# STM32H7P5 register map
File version: 2.0.0
CPU: CM7 r1p2, little endian, MPU, FPU, 4 interrupt priority bits
Registers are 32-bit, read-write, reset 0x0 unless marked. A register's access mark holds for its fields unless they carry their own. Offsets are from the block's base; [hi:lo] are bit positions; lines under a group give offsets from that group; {n}, {i} and the like mark numbered series; 'fields as' and 'values as' point back to an identical list.

## I3C1 — I3C register block
Base 0x40006000
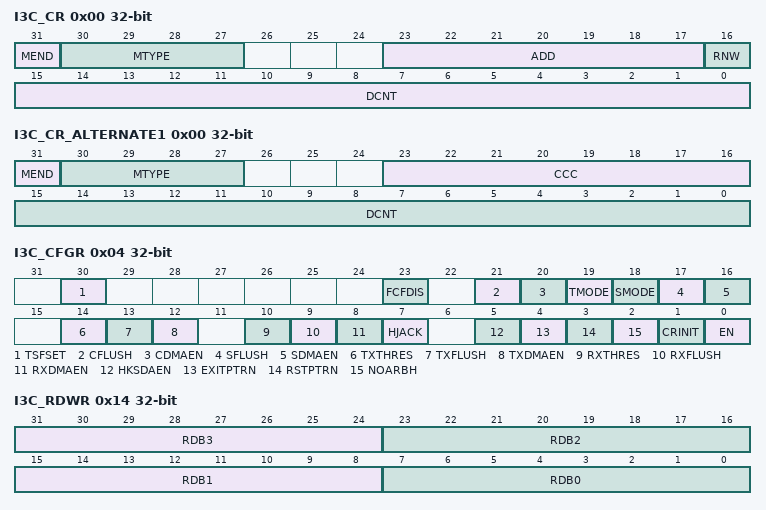
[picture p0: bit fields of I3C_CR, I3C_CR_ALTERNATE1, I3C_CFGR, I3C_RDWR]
0x00 I3C_CR wo — I3C message control register
  [31] MEND — Message end type/last message of a frame (when the I3C acts as controller)
    0=this message from controller is followed by a repeated start (Sr), before another message must be emitted; 1=this message from controller ends with a stop (P), being the last message of a frame
  [30:27] MTYPE — Message type (whatever I3C acts as controller/target)
    0=B_0x0_WHEN_I3C_ACTS_AS_I3C_CONTROLLER (SCL clock is forced to stop until a next control word is executed); 1=B_0x1_WHEN_I3C_ACTS_AS_I3C_CONTROLLER (header message); 2=B_0x2_WHEN_I3C_ACTS_AS_I3C_CONTROLLER (private message (refer to Figure726)); 3=B_0x3_WHEN_I3C_ACTS_AS_I3C_CONTROLLER (direct message (second part of an I3C SDR direct CCC command) (refer to Figure719)); 4=B_0x4_WHEN_I3C_ACTS_AS_I3C_CONTROLLER (legacy Iless thansup>2less than/sup>C message (refer to Figure728)); 8=B_0x8_WHEN_I3C_ACTS_AS_I3C_TARGET (hot-join request (W) (refer to Figure731)); 9=B_0x9_WHEN_I3C_ACTS_AS_I3C_TARGET (controller-role request (W) (refer to Figure732)); 10=B_0xA_WHEN_I3C_ACTS_AS_I3C_TARGET (IBI (in-band interrupt) request (R) (refer to Figure730))
  [23:17] ADD — 7-bit I3C dynamic / Iless thansup>2less than/sup>C static target address (when I3C acts as controller)
  [16] RNW — Read / non-write message (when I3C acts as controller)
    0=write message; 1=read message
  [15:0] DCNT — Count of data to transfer during a read or write message, in bytes (whatever I3C acts as controller/target)
    0=no data to transfer; 1=1 byte; 2=2 bytes; 0xFFFF=64 Kbytes - 1 byte
0x00 I3C_CR_ALTERNATE1 wo (alternate view of I3C_CR) — I3C message control register
  [31] MEND — Message end type/last message of a frame (when I3C acts as controller)
    0=this message from controller is followed by a repeated start (Sr), before another message must be emitted; 1=the message from the controller ends with a stop (P), being the last message of a frame
  [30:27] MTYPE — Message type (when I3C acts as controller)
    6=B_0x6_WHEN_I3C_ACTS_AS_I3C_CONTROLLER (broadcast/direct CCC command (refer to Table556, Figure719, Figure720, Figure721))
  [23:16] CCC — 8-bit CCC code (when I3C acts as controller)
  [15:0] DCNT — Count of related data to the CCC command to transfer as CCC defining bytes, or CCC sub-command bytes, or CCC data bytes, in bytes
    values as I3C_CR.DCNT
0x04 I3C_CFGR — I3C configuration register
  [30] TSFSET wo — Frame transfer set (software trigger) (when I3C acts as controller)
    0=no action; 1=setting this bit initiates a frame transfer by causing the hardware to assert the flag CFNFF in the I3C_EVR register (C-FIFO not full and a control word is needed)
  [23] FCFDIS — FCF generation disable (when I3C acts as controller)
    0=enable the generation of the flag FCF in the I3C_EVR register; 1=disable the generation of the flag FCF in the I3C_EVR register
  [21] CFLUSH wo — C-FIFO flush (when I3C acts as controller)
    0=no action; 1=flush C-FIFO
  [20] CDMAEN — C-FIFO DMA request enable (when I3C acts as controller)
    0=DMA mode is disabled for C-FIFO; 1=DMA mode is enabled for C-FIFO
  [19] TMODE — Transmit mode (when I3C acts as controller)
    0=C-FIFO and TX-FIFO are not preloaded before starting to emit a frame transfer; 1=C-FIFO and TX-FIFO are first preloaded (also TX-FIFO if needed, depending on the frame format) before starting to emit a frame transfer. Refer to Section52.10.2 for more details.
  [18] SMODE — S-FIFO enable / status receive mode (when I3C acts as controller)
    0=S-FIFO is disabled; 1=S-FIFO is enabled
  [17] SFLUSH wo — S-FIFO flush (when I3C acts as controller)
    0=no action; 1=flush S-FIFO
  [16] SDMAEN — S-FIFO DMA request enable (when I3C acts as controller)
    0=DMA mode is disabled for reading status register I3C_SR; 1=DMA mode is enabled for reading status register I3C_SR
  [14] TXTHRES — TX-FIFO threshold (whatever I3C acts as controller/target)
    0=1-byte threshold; 1=1-word / 4-byte threshold
  [13] TXFLUSH wo — TX-FIFO flush (whatever I3C acts as controller/target)
    0=no action; 1=flush TX-FIFO
  [12] TXDMAEN — TX-FIFO DMA request enable (whatever I3C acts as controller/target)
    0=DMA mode is disabled for TX-FIFO; 1=DMA mode is enabled for TX-FIFO
  [10] RXTHRES — RX-FIFO threshold (whatever I3C acts as controller/target)
    0=1-byte threshold; 1=1-word/4-bytes threshold
  [9] RXFLUSH wo — RX-FIFO flush (whatever I3C acts as controller/target)
    0=no action; 1=flush RX-FIFO
  [8] RXDMAEN — RX-FIFO DMA request enable (whatever I3C acts as controller/target)
    0=DMA mode is disabled for RX-FIFO; 1=DMA mode is enabled for RX-FIFO
  [7] HJACK — Hot-join request acknowledge (when I3C acts as a controller)
    0=hot-join request is not acknowledged; 1=hot-join request is acknowledged
  [5] HKSDAEN — High-keeper enable on SDA line (when I3C acts as a controller)
    0=High-keeper is disabled; 1=High-keeper is enabled, and the weak pull-up is effective on the T bit, instead of the open-drain class pull-up
  [4] EXITPTRN — HDR exit pattern enable (when I3C acts as a controller)
    0=HDR exit pattern is not sent after the issued message header (MTYPE[3:0]=0001 in the I3C_CR register). This is used to send the header, to test ownership of the bus when there is a suspicion of a problem after controller-role hand-off (new controller did not assert its controller-role by accessing the previous one in less than the delay defined by the activity state).; 1=HDR exit pattern is sent after the issued message header (MTYPE[3:0]=0001). This is used on a controller error detection and escalation handling, in case of a not responding target to a private message or a direct read CCC.
  [3] RSTPTRN — HDR reset pattern enable (when I3C acts as a controller)
    0=standard stop emitted at the end of a frame; 1=HDR reset pattern is inserted before the stop of any emitted frame that includes a RSTACT CCC command
  [2] NOARBH — No arbitrable header after a start (when I3C acts as a controller)
    0=An arbitrable header (0b111_1110 + RnW = 0) is emitted after a start and before a legacy Iless thansup>2less than/sup>C message or an I3C SDR private read/write message (default); 1=No arbitrable header
  [1] CRINIT — Initial controller/target role
    0=target role; 1=controller role
  [0] EN — I3C enable (whatever I3C acts as controller/target)
    0=I3C is disabled; 1=I3C is enabled
0x10 I3C_RDR ro — I3C receive data byte register
  [7:0] RDB0 — 8-bit received data on I3C bus.
0x14 I3C_RDWR ro — I3C receive data word register
  [31:24] RDB3 — 8-bit received data (latest byte on I3C bus).
  [23:16] RDB2 — 8-bit received data (next byte after RDB1 on I3C bus).
  [15:8] RDB1 — 8-bit received data (next byte after RDB0 on I3C bus).
  [7:0] RDB0 — 8-bit received data (earliest byte on I3C bus).
0x18 I3C_TDR wo — I3C transmit data byte register
  [7:0] TDB0 — 8-bit data to transmit on I3C bus.
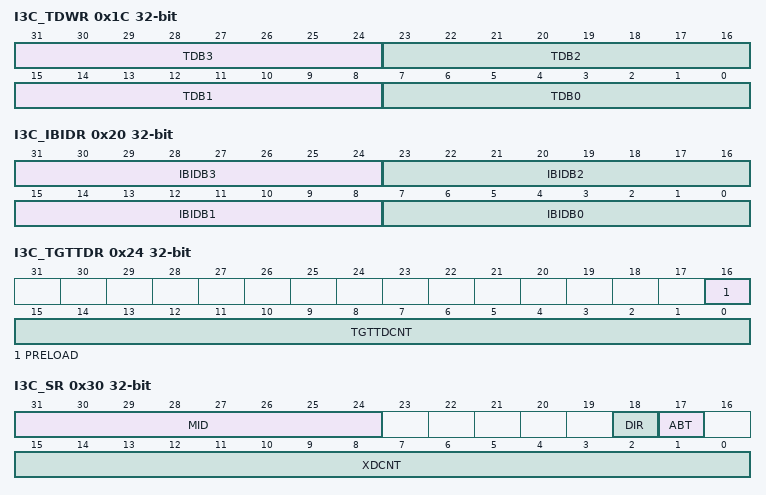
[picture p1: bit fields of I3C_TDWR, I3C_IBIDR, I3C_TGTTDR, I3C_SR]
0x1C I3C_TDWR wo — I3C transmit data word register
  [31:24] TDB3 — 8-bit transmit data (latest byte on I3C bus).
  [23:16] TDB2 — 8-bit transmit data (next byte after TDB1[7:0] on I3C bus).
  [15:8] TDB1 — 8-bit transmit data (next byte after TDB0[7:0] on I3C bus).
  [7:0] TDB0 — 8-bit transmit data (earliest byte on I3C bus)
0x20 I3C_IBIDR — I3C IBI payload data register
  [31:24] IBIDB3 — 8-bit IBI payload data (latest byte on I3C bus).
  [23:16] IBIDB2 — 8-bit IBI payload data (next byte on I3C bus after IBIDB1[7:0]).
  [15:8] IBIDB1 — 8-bit IBI payload data (next byte on I3C bus after IBIDB0[7:0]).
  [7:0] IBIDB0 — 8-bit IBI payload data (earliest byte on I3C bus, MDB[7:0] mandatory data byte).
0x24 I3C_TGTTDR — I3C target transmit configuration register
  [16] PRELOAD — Preload of the TX-FIFO (when I3C is configured as target)
    0=no TX-FIFO preload; 1=TX-FIFO preload
  [15:0] TGTTDCNT — Transmit data counter, in bytes (when I3C is configured as target)
0x30 I3C_SR ro — I3C status register
  [31:24] MID — Message identifier/counter of a given frame (when the I3C acts as controller)
  [18] DIR — Message direction
    0=write; 1=read
  [17] ABT — A private read message is ended prematurely by the target (when the I3C acts as controller)
    0=no early completion from the target; 1=early completion from the target
  [15:0] XDCNT — Data counter
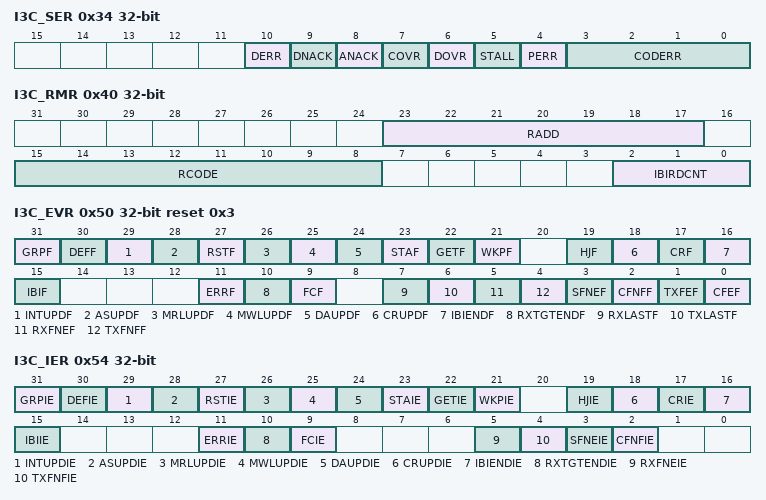
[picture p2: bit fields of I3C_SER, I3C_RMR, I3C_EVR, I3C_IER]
0x34 I3C_SER ro — I3C status error register
  [10] DERR — Data error (when the I3C acts as controller)
    0=no detected error; 1=controller detected a data error during the controller-role hand-off procedure (GETACCCR CCC, formerly known as GETACCMST) when the received target address or/and the parity bit do no match. Active controller keeps controller-role.
  [9] DNACK — Data not acknowledged (when the I3C acts as controller)
    0=no detected error; 1=controller detected that a data byte is not acknowledged by a target, either during:
  [8] ANACK — Address not acknowledged (when the I3C is configured as controller)
    0=no detected error; 1=controller detected that the static/dynamic address was not acknowledged by a target, either during:
  [7] COVR — C-FIFO underrun or S-FIFO overrun (when the I3C acts as controller)
    0=no detected error; 1=controller detected either:
  [6] DOVR — RX-FIFO overrun or TX-FIFO underrun
    0=no detected error; 1=whatever controller or target, hardware detected either:
  [5] STALL — SCL stall error (when the I3C acts as target)
    0=no detected error; 1=target detected that SCL was stable for more than 125 us during an I3C SDR data read (during a direct CCC read, a private read, or an IB)
  [4] PERR — Protocol error
    0=no detected error; 1=whatever controller or target, hardware detected a protocol error, as detailed in CODERR[3:0]
  [3:0] CODERR — Protocol error code/type
    0=CE0 error (transaction after sending CCC):; 1=CE1 error (monitoring error):; 2=CE2 error (no response to broadcast address):; 3=CE3 error (failed controller-role hand-off):; 8=TE0 error (invalid broadcast address 0b111_1110 + W):; 9=TE1 error (CCC code):; 10=TE2 error (write data):; 11=TE3 error (assigned address during dynamic address arbitration):; 12=TE4 error (0b111_1110 + R missing after Sr during dynamic address arbitration):; 13=TE5 error (transaction after detecting CCC):; 14=TE6 error (monitoring error):
0x40 I3C_RMR ro — I3C received message register
  [23:17] RADD — Received target address (when the I3C is configured as controller)
  [15:8] RCODE — Received CCC code (when the I3C is configured as target)
  [2:0] IBIRDCNT — IBI received payload data count (when the I3C is configured as controller)
0x50 I3C_EVR ro reset 0x3 — I3C event register
  [31] GRPF — Group addressing flag (when the I3C acts as target)
  [30] DEFF — DEFTGTS flag (when the I3C acts as target)
  [29] INTUPDF — Interrupt/controller-role/hot-join update flag (when the I3C acts as target)
  [28] ASUPDF — Activity state update flag (when the I3C acts as target)
  [27] RSTF — Reset pattern flag (when the I3C acts as target)
  [26] MRLUPDF — Maximum read length update flag (when the I3C acts as target)
  [25] MWLUPDF — Maximum write length update flag (when the I3C acts as target)
  [24] DAUPDF — Dynamic address update flag (when the I3C acts as target)
  [23] STAF — Get status flag (when the I3C acts as target)
  [22] GETF — Get flag (when the I3C acts as target)
  [21] WKPF — Wake-up/missed start flag (when the I3C acts as target)
  [19] HJF — Hot-join flag (when the I3C acts as controller)
  [18] CRUPDF — Controller-role update flag (when the I3C acts as target)
  [17] CRF — Controller-role request flag (when the I3C acts as controller)
  [16] IBIENDF — IBI end flag (when the I3C acts as target)
  [15] IBIF — IBI flag (when the I3C acts as controller)
  [11] ERRF — Flag (whatever the I3C acts as controller/target)
  [10] RXTGTENDF — Target-initiated read end flag (when the I3C acts as controller)
  [9] FCF — Frame complete flag (whatever the I3C acts as controller/target)
  [7] RXLASTF — Last read data byte/word flag (when the I3C acts as controller)
  [6] TXLASTF — Last written data byte/word flag (whatever the I3C acts as controller/target)
  [5] RXFNEF — RX-FIFO not empty flag (whatever the I3C acts as controller/target)
  [4] TXFNFF — TX-FIFO not full flag (whatever the I3C acts as controller/target)
  [3] SFNEF — S-FIFO not empty flag (when the I3C acts as controller)
  [2] CFNFF — C-FIFO not full flag (when the I3C acts as controller)
  [1] TXFEF — TX-FIFO empty flag (whatever the I3C acts as controller/target)
  [0] CFEF — C-FIFO empty flag (whatever the I3C acts as controller)
0x54 I3C_IER — I3C interrupt enable register
  [all] fields
    0=interrupt disabled; 1=interrupt enabled
  [31] GRPIE — DEFGRPA CCC interrupt enable (when the I3C acts as target)
  [30] DEFIE — DEFTGTS CCC interrupt enable (when the I3C acts as target)
  [29] INTUPDIE — ENEC/DISEC CCC interrupt enable (when the I3C acts as target)
  [28] ASUPDIE — ENTASx CCC interrupt enable (when the I3C acts as target)
  [27] RSTIE — reset pattern interrupt enable (when the I3C acts as target)
  [26] MRLUPDIE — SETMRL CCC interrupt enable (when the I3C acts as target)
  [25] MWLUPDIE — SETMWL CCC interrupt enable (when the I3C acts as target)
  [24] DAUPDIE — ENTDAA/RSTDAA/SETNEWDA CCC interrupt enable (when the I3C acts as target)
  [23] STAIE — format 1 GETSTATUS CCC interrupt enable (when the I3C acts as target)
  [22] GETIE — GETxxx CCC interrupt enable (except GETSTATUS of format 1) (when the I3C acts as target)
  [21] WKPIE — Wake-up interrupt enable (when the I3C acts as target)
  [19] HJIE — Hot-join interrupt enable (when the I3C acts as controller)
  [18] CRUPDIE — Controller-role update interrupt enable (when the I3C acts as target)
  [17] CRIE — Controller-role request interrupt enable (when the I3C acts as controller)
  [16] IBIENDIE — IBI end interrupt enable (when the I3C acts as target)
  [15] IBIIE — IBI request interrupt enable (when the I3C acts as controller)
  [11] ERRIE — error interrupt enable (whatever the I3C acts as controller/target)
  [10] RXTGTENDIE — target-initiated read end interrupt enable (when the I3C acts as controller)
  [9] FCIE — frame complete interrupt enable (whatever the I3C acts as controller/target)
  [5] RXFNEIE — RX-FIFO not empty interrupt enable (whatever the I3C acts as controller/target)
  [4] TXFNFIE — TX-FIFO not full interrupt enable (whatever the I3C acts as controller/target)
  [3] SFNEIE — S-FIFO not empty interrupt enable when the I3C acts as controller
  [2] CFNFIE — C-FIFO not full interrupt enable when the I3C acts as controller
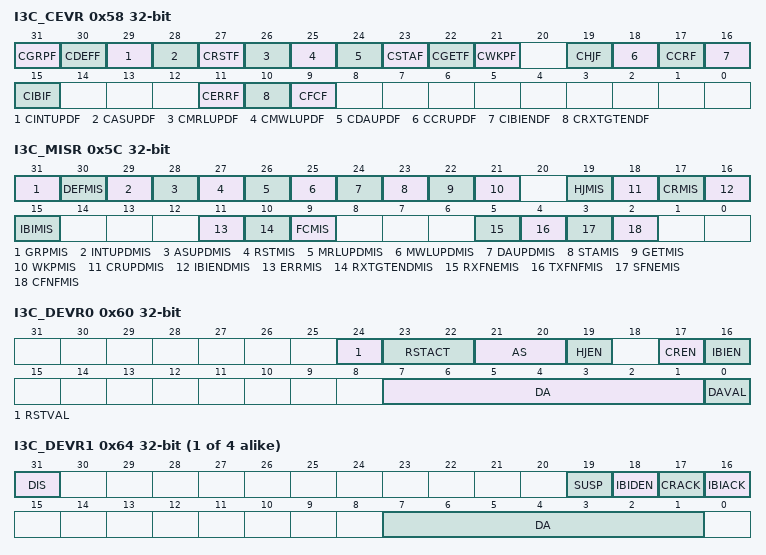
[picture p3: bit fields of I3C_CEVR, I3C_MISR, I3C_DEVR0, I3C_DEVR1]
0x58 I3C_CEVR wo — I3C clear event register
  [31] CGRPF — Clear DEFGRPA CCC flag (when the I3C acts as target)
    0=no effect; 1=clear GRPF
  [30] CDEFF — Clear DEFTGTS CCC flag (when the I3C acts as target)
    0=no effect; 1=clear DEFF
  [29] CINTUPDF — Clear ENEC/DISEC CCC flag (when the I3C acts as target)
    0=no effect; 1=clear CINTUPDF
  [28] CASUPDF — Clear ENTASx CCC flag (when the I3C acts as target)
    0=no effect; 1=clear ASUPDF
  [27] CRSTF — Clear reset pattern flag (when the I3C acts as target)
    0=no effect; 1=clear RSTF
  [26] CMRLUPDF — Clear SETMRL CCC flag (when the I3C acts as target)
    0=no effect; 1=clear MRLUPDF
  [25] CMWLUPDF — Clear SETMWL CCC flag (when the I3C acts as target)
    0=no effect; 1=clear MWLUPDF
  [24] CDAUPDF — Clear ENTDAA/RSTDAA/SETNEWDA CCC flag (when the I3C acts as target)
    0=no effect; 1=clear DAUPDF
  [23] CSTAF — Clear format 1 GETSTATUS CCC flag (when the I3C acts as target)
    0=no effect; 1=clear STAF
  [22] CGETF — Clear GETxxx CCC flag (except GETSTATUS of format 1) (when the I3C acts as target)
    0=no effect; 1=clear GETF
  [21] CWKPF — Clear wake-up flag (when the I3C acts as target)
    0=no effect; 1=clear WKPF
  [19] CHJF — Clear hot-join flag (when the I3C acts as controller)
    0=no effect; 1=clear HJF
  [18] CCRUPDF — Clear controller-role update flag (when the I3C acts as target)
    0=no effect; 1=clear CRUPDF
  [17] CCRF — Clear controller-role request flag (when the I3C acts as controller)
    0=no effect; 1=clear CRF
  [16] CIBIENDF — Clear IBI end flag (when the I3C acts as target)
    0=no effect; 1=clear IBIENDF
  [15] CIBIF — Clear IBI request flag (when the I3C acts as controller)
    0=no effect; 1=clear IBIF
  [11] CERRF — Clear error flag (whatever the I3C acts as controller/target)
    0=no effect; 1=clear ERRF
  [10] CRXTGTENDF — Clear target-initiated read end flag (when the I3C acts as controller)
    0=no effect; 1=clear RXTGTENDF
  [9] CFCF — Clear frame complete flag (whatever the I3C acts as controller/target)
    0=no effect; 1=clear FCF
0x5C I3C_MISR ro — I3C masked interrupt status register
  [31] GRPMIS — DEFGRPA CCC masked interrupt status (when the I3C acts as target)
  [30] DEFMIS — DEFTGTS CCC masked interrupt status (when the I3C acts as target)
  [29] INTUPDMIS — ENEC/DISEC CCC masked interrupt status (when the I3C acts as target)
  [28] ASUPDMIS — ENTASx CCC masked interrupt status (when the I3C acts as target)
  [27] RSTMIS — reset pattern masked interrupt status (when the I3C acts as target)
  [26] MRLUPDMIS — SETMRL CCC masked interrupt status (when the I3C acts as target)
  [25] MWLUPDMIS — SETMWL CCC masked interrupt status (when the I3C acts as target)
  [24] DAUPDMIS — ENTDAA/RSTDAA/SETNEWDA CCC masked interrupt status (when the I3C acts as target)
  [23] STAMIS — format 1 GETSTATUS CCC masked interrupt status (when the I3C acts as target)
  [22] GETMIS — GETxxx CCC masked interrupt status, except GETSTATUS of format 1 (when the I3C acts as target)
  [21] WKPMIS — Wake-up/missed start masked interrupt status (when the I3C acts as target)
  [19] HJMIS — Hot-join masked interrupt status (when the I3C acts as controller)
  [18] CRUPDMIS — Controller-role update masked interrupt status (when the I3C acts as target)
  [17] CRMIS — Controller-role request masked interrupt status (when the I3C acts as controller)
  [16] IBIENDMIS — IBI end masked interrupt status (when the I3C acts as target)
  [15] IBIMIS — IBI request masked interrupt status (when the I3C acts as controller)
  [11] ERRMIS — error masked interrupt status (whatever the I3C acts as controller/target)
  [10] RXTGTENDMIS — target-initiated read end masked interrupt status (when the I3C acts as controller)
  [9] FCMIS — frame complete masked interrupt status (whatever the I3C acts as controller/target)
  [5] RXFNEMIS — RX-FIFO not empty masked interrupt status (whatever the I3C acts as controller/target)
  [4] TXFNFMIS — TX-FIFO not full masked interrupt status (whatever the I3C acts as controller/target)
  [3] SFNEMIS — S-FIFO not empty masked interrupt status (when the I3C acts as controller)
  [2] CFNFMIS — C-FIFO not full masked interrupt status (when the I3C acts as controller)
0x60 I3C_DEVR0 — I3C own device characteristics register
  [24] RSTVAL ro — Reset action is valid (when the I3C acts as target)
  [23:22] RSTACT ro — Reset action/level on received reset pattern (when the I3C acts as target)
    0=no reset action; 1=first level of reset: the application software must either:; 2=second level of reset: the application software must issue a warm reset, also known as a system reset. This (see ) has the same impact as a pin reset (NRST = 0):; 3=no reset action
  [21:20] AS ro — Activity state (when the I3C acts as target)
    {v}=activity state {v} (v=0..3)
  [19] HJEN — Hot-join request enable (when the I3C acts as target)
    0=hot-join request disabled; 1=hot-join request enabled
  [17] CREN — Controller-role request enable (when the I3C acts as target)
    0=controller-role request disabled; 1=controller-role request enabled
  [16] IBIEN — IBI request enable (when the I3C acts as target)
    0=IBI request disabled; 1=IBI request enabled
  [7:1] DA — 7-bit dynamic address
  [0] DAVAL — Dynamic address is valid (when the I3C acts as target)
{0x60+4i} I3C_DEVR{i} (i=1..4) — I3C device {i} characteristics register
  [31] DIS ro — Disables writes to DA[6:0] (when the I3C acts as controller)
    0=write to DA[7:0] and to IBIDEN in the I3C_DEVRx register is allowed; 1=write to DA[7:0] and to IBIDEN is disabled/locked
  [19] SUSP — Suspend/stop I3C transfer on received IBI (when the I3C acts as controller)
    0=C-FIFO and TX-FIFO are not flushed after an IBI request from target x is acknowledged and completed, and depending on the presence or absence of a next control word, a repeated start or a stop is emitted; 1=I3C transfer is stopped and both C-FIFO and TX-FIFO are flushed after receiving an IBI request from target x
  [18] IBIDEN — IBI data enable (when the I3C acts as controller)
    0=no data byte follows the acknowledged IBI from target x; 1=the mandatory data byte MDB[7:0] follows the acknowledged IBI from target x
  [17] CRACK — Controller-role request acknowledge (when the I3C acts as controller)
    0=a controller-role request from target x must be NACK-ed; 1=a controller-role request (with 7-bit dynamic address DA[6:0]) from target x must be ACKed
  [16] IBIACK — IBI request acknowledge (when the I3C acts as controller)
    0=an IBI request from target x must be NACK-ed; 1=an IBI request (with 7-bit dynamic address DA[6:0]) from target x must be ACKed
  [7:1] DA — Assigned I3C dynamic address to target x (when the I3C acts as controller)
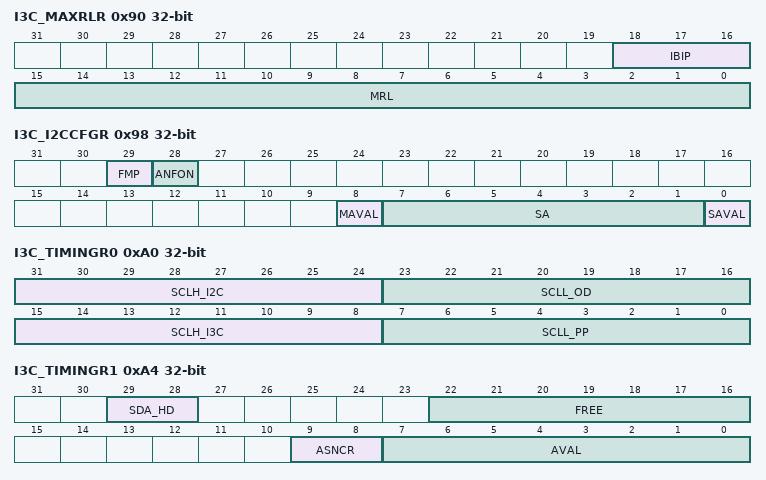
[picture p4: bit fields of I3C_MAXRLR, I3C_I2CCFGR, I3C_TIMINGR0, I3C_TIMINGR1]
0x90 I3C_MAXRLR — I3C maximum read length register
  [18:16] IBIP — IBI payload data maximum size, in bytes (when I3C acts as target)
    0=null payload data size (only allowed when BCR2 = 0 in the I3C_BCR register); 1=1 byte (mandatory data byte MDB[7:0]; 2=2 bytes (including first MDB[7:0]); 3=3 bytes (including first MDB[7:0]); 4=4 bytes (including first MDB[7:0])
  [15:0] MRL — Maximum data read length (when I3C acts as target)
0x94 I3C_MAXWLR — I3C maximum write length register
  [15:0] MWL — Maximum data write length (when I3C acts as target)
0x98 I3C_I2CCFGR — I3C IC target configuration register
  [29] FMP — high drive enable for Fast Mode plus (when the I3C peripheral is initialized as target)
    0=initialized with a disabled 20 mA drive; 1=initialized with an enabled 20 mA drive
  [28] ANFON — analog filter enable (when the I3C peripheral is initialized as target)
    0=initialized with a disabled 50 ns spike filter; 1=initialized with an enabled 50 ns spike filter
  [8] MAVAL — Minimum I3C target address 7'h01 is valid (when the I3C peripheral is initialized as target)
    0=Minimum address 7'h01 is not valid: a direct SETDASA with 7'h01 address is not acknowledged; 1=Minimum address 7'h01 is valid: a direct SETDASA CCC with 7'h01 address is acknowledged
  [7:1] SA — 7-bit static address (when the I3C peripheral is initialized as target)
  [0] SAVAL — Static address is valid (when the I3C peripheral is initialized as target)
    0=initialized without a static address. Typical I3C target usage with ENTDAA; 1=initialized with a valid static address on an Iless thansup>2less than/sup>C bus or an I3C bus with SETDASA/SETAASA
0xA0 I3C_TIMINGR0 — I3C timing register 0
  [31:24] SCLH_I2C — SCL high duration, used for legacy Iless thansup>2less than/sup>C messages, in number of kernel clocks cycles:
  [23:16] SCLL_OD — SCL low duration in open-drain phases, used for legacy Iless thansup>2less than/sup>C messages and for I3C open-drain phases (address phase following a start, ACK phase during controller-initiated messages, and T bit phase during direct/private/IBI payload), in number of kernel clocks cycles:
  [15:8] SCLH_I3C — SCL high duration, used for I3C messages (both in push-pull and open-drain phases), in number of kernel clocks cycles:
  [7:0] SCLL_PP — SCL low duration in I3C push-pull phases, in number of kernel clocks cycles:
0xA4 I3C_TIMINGR1 — I3C timing register 1
  [29:28] SDA_HD — SDA hold time (when the I3C acts as controller), in number of kernel clocks cycles (refer to MIPI timing SDA hold time in push-pull tless thansub>HD_PPless than/sub>):
  [22:16] FREE — Number of kernel clocks cycles that is used to set some MIPI timings like bus free condition time (when the I3C acts as controller)
  [9:8] ASNCR — Activity state of the new controller (when I3C acts as active controller)
  [7:0] AVAL — Number of kernel clock cycles to set a time unit of 1 us, whatever I3C acts as controller or target.
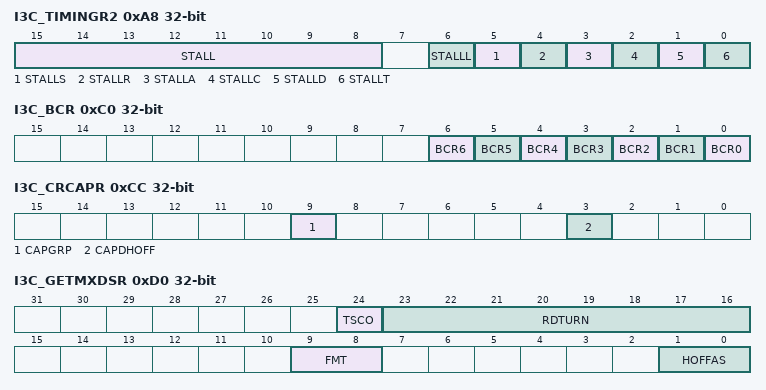
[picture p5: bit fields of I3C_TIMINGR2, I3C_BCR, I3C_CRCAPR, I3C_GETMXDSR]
0xA8 I3C_TIMINGR2 — I3C timing register 2
  [15:8] STALL — Controller clock stall time, in number of kernel clock cycles
  [6] STALLL — Controller clock stall enable in the address ACK/NACK phase (before the ninth bit) of a legacy I2C read/write message. This allows the I2C target to prepare the next data byte to send/receive.
    0=no stall; 1=stall enabled
  [5] STALLS — Controller clock stall enable in the data ACK/NACK phase of a legacy I2C write message. This allows the I2C target to prepare the next data byte to receive.
    0=no stall; 1=stall enabled
  [4] STALLR — Controller clock stall enable in the data ACK/NACK phase of a legacy I2C read message. This allows the I2C target to prepare the next data byte to send.
    0=no stall; 1=stall enabled
  [3] STALLA — Controller clock stall enable on ACK phase
    0=no stall; 1=stall enabled
  [2] STALLC — Controller clock stall enable on PAR phase of CCC
    0=no stall; 1=stall enabled
  [1] STALLD — Controller clock stall enable on PAR phase of Data
    0=no stall; 1=stall enabled
  [0] STALLT — Controller clock stall enable on T-bit phase of data
    0=no stall; 1=stall enabled
0xC0 I3C_BCR — I3C bus characteristics register
  [6] BCR6 — Controller capable
    0=I3C target (no controller capable); 1=I3C controller capable
  [5] BCR5 ro — advanced capabilities, use GETCAPS CCC to determine which ones
    1=advanced capabilities, use GETCAPS CCC to determine which ones
  [4] BCR4 ro — not a virtual target
    0=not a virtual target
  [3] BCR3 ro — offline capable
    1=offline capable
  [2] BCR2 — in-band interrupt (IBI) payload
    0=no data byte follows the accepted IBI; 1=at least one mandatory data byte follows the accepted IBI (and at most 4 data bytes)
  [1] BCR1 ro — IBI request capable
    1=IBI request capable
  [0] BCR0 — max data speed limitation
    0=no limitation; 1=limitation, as described by I3C_GETMXDSR
0xC4 I3C_DCR — I3C device characteristics register
  [7:0] DCR — device characteristics ID
    0=generic device (for v1.0 devices)
0xC8 I3C_GETCAPR — I3C get capability register
  [14] CAPPEND — IBI MDB support for pending read notification
    0=this I3C when acting as target sends an IBI request without a mandatory data byte value indicating a pending read notification; 1=this I3C when acting as target sends an IBI request with a mandatory data byte value (MDB[7:5] = 101), indicating a pending read notification
0xCC I3C_CRCAPR — I3C controller-role capability register
  [9] CAPGRP — group management support (when acting as controller)
    0=this I3C does not support group address capabilities; 1=this I3C supports group address capabilities (when becoming controller)
  [3] CAPDHOFF — delayed controller-role hand-off
    0=this I3C does not needs additional time to process a controller-role hand-off; 1=this I3C needs additional time to process a controller-role hand-off
0xD0 I3C_GETMXDSR — I3C get max data speed register
  [24] TSCO — clock-to-data turnaround time (tless thansub>SCOless than/sub>)
    0=tless thansub>SCOless than/sub> less than or equal to 12 ns; 1=tless thansub>SCOless than/sub> > 12 ns (refer to the datasheet for more details)
  [23:16] RDTURN — programmed byte of the 3-byte MaxRdTurn (maximum read turnaround byte)
  [9:8] FMT — GETMXDS CCC format
    0=format 1 (2 bytes with MaxWr with no defining byte, MaxRd); 1=format 2: (5 bytes w.ith MaxWr with no defining byte, MaxRd, MaxRdTurn); 2=format 2 (5 bytes with MaxWr with no defining byte, MaxRd, and middle byte of MaxRdTurn); 3=format 2 (5 bytes with MaxWr with no defining byte, MaxRd, MSB of MaxRdTurn)
  [1:0] HOFFAS — Controller hand-off activity state
    0=activity state 0 is the initial activity state of this I3C before and when becoming controller; 1=activity state 1 is the initial activity state of this I3C when becoming controller; 2=activity state 2 is the initial activity state of this I3C when becoming controller; 3=activity state 3 is the initial activity state of this I3C when becoming controller
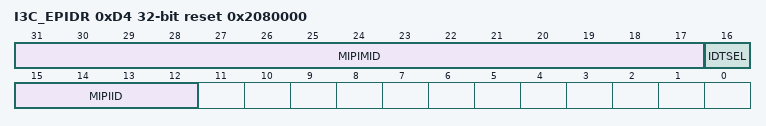
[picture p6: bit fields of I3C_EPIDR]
0xD4 I3C_EPIDR reset 0x2080000 — I3C extended provisioned ID register
  [31:17] MIPIMID ro — 15-bit MIPI manufacturer ID
  [16] IDTSEL ro — provisioned ID type selector
  [15:12] MIPIID — 4-bit MIPI Instance ID
